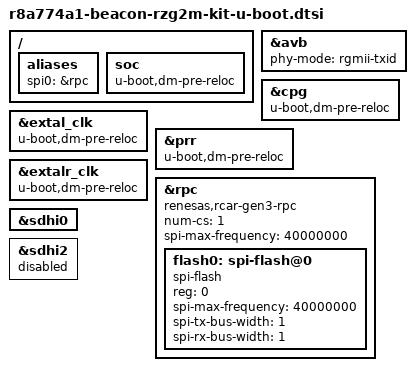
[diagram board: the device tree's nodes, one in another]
// SPDX-License-Identifier: GPL-2.0
/*
 * Copyright 2020 Compass Electronics Group, LLC
 */

/ {
	aliases {
		spi0 = &rpc;
	};

	soc {
		u-boot,dm-pre-reloc;
	};
};

&avb {
	phy-mode = "rgmii-txid";
};

&cpg {
	u-boot,dm-pre-reloc;
};

&extal_clk {
	u-boot,dm-pre-reloc;
};

&prr {
	u-boot,dm-pre-reloc;
};

&extalr_clk {
	u-boot,dm-pre-reloc;
};

&rpc {
	compatible = "renesas,rcar-gen3-rpc";
	num-cs = <1>;
	spi-max-frequency = <40000000>;
	#address-cells = <1>;
	#size-cells = <0>;
	status = "okay";

	flash0: spi-flash@0 {
		#address-cells = <1>;
		#size-cells = <1>;
		reg = <0>;
		compatible = "spi-flash", "jedec,spi-nor";
		spi-max-frequency = <40000000>;
		spi-tx-bus-width = <1>;
		spi-rx-bus-width = <1>;
	};
};

&sdhi0 {
	/delete-property/ cd-gpios;
};

&sdhi2 {
	status = "disabled";
};
